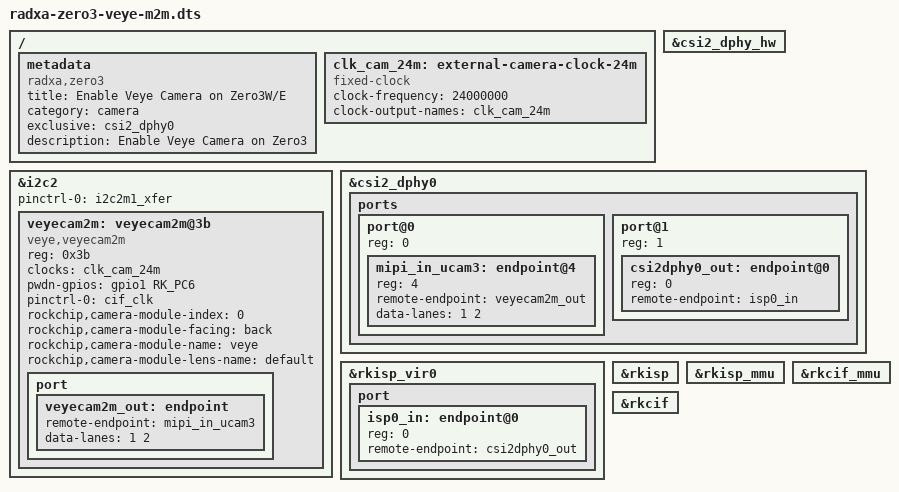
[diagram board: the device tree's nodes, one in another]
/*
 * Copyright (C) 2024 Raphael from OpenHD
 *
 * This is free software: you can redistribute it and/or modify
 * it under the terms of the GNU General Public License as published by
 * the Free Software Foundation, either version 3 of the License, or
 * (at your option) any later version.
 *
 * This is distributed in the hope that it will be useful,
 * but WITHOUT ANY WARRANTY; without even the implied warranty of
 * MERCHANTABILITY or FITNESS FOR A PARTICULAR PURPOSE. See the
 * GNU General Public License for more details.
 *
 */

/dts-v1/;
/plugin/;

#include <dt-bindings/gpio/gpio.h>
#include <dt-bindings/pinctrl/rockchip.h>

/ {
	metadata {
		title = "Enable Veye Camera on Zero3W/E";
		compatible = "radxa,zero3";
		category = "camera";
		exclusive = "csi2_dphy0";
		description = "Enable Veye Camera on Zero3";
	};

	fragment@0 {
		target-path = "/";

		__overlay__ {		
			clk_cam_24m: external-camera-clock-24m {
				status = "okay";
				compatible = "fixed-clock";
				clock-frequency = <24000000>;
				clock-output-names = "clk_cam_24m";
				#clock-cells = <0>;
			};
		};
	};

	fragment@1 {
		target = <&i2c2>;

		__overlay__ {
			status = "okay";
			pinctrl-names = "default";
			pinctrl-0 = <&i2c2m1_xfer>;
			#address-cells = <1>;
			#size-cells = <0>;

			veyecam2m: veyecam2m@3b {
				status = "okay";
				compatible = "veye,veyecam2m";
				reg = <0x3b>;
				clocks = <&clk_cam_24m>;
		 		clock-names = "xvclk";
				pwdn-gpios = <&gpio1 RK_PC6 GPIO_ACTIVE_HIGH>;
				pinctrl-names = "default";
				pinctrl-0 = <&cif_clk>;
				rockchip,camera-module-index = <0>;
				rockchip,camera-module-facing = "back";
				rockchip,camera-module-name = "veye";
				rockchip,camera-module-lens-name = "default";

				port {
					veyecam2m_out: endpoint {
						remote-endpoint = <&mipi_in_ucam3>;
						data-lanes = <1 2>;
					};
				};
			};
		};
	};

	fragment@2 {
		target = <&csi2_dphy_hw>;

		__overlay__ {
			status = "okay";
		};
	};

	fragment@3 {
		target = <&csi2_dphy0>;

		__overlay__ {
			status = "okay";

			ports {
				#address-cells = <1>;
				#size-cells = <0>;

				port@0 {
					reg = <0>;
					#address-cells = <1>;
					#size-cells = <0>;

					mipi_in_ucam3: endpoint@4 {
						reg = <4>;
						remote-endpoint = <&veyecam2m_out>;
						data-lanes = <1 2>;
					};
				};

				port@1 {
					reg = <1>;
					#address-cells = <1>;
					#size-cells = <0>;

					csi2dphy0_out: endpoint@0 {
						reg = <0>;
						remote-endpoint = <&isp0_in>;
					};
				};
			};
		};
	};

	fragment@4 {
		target = <&rkisp_vir0>;

		__overlay__ {
			status = "okay";

			port {
				#address-cells = <1>;
				#size-cells = <0>;

				isp0_in: endpoint@0 {
					reg = <0>;
					remote-endpoint = <&csi2dphy0_out>;
				};
			};
		};
	};

	fragment@5 {
		target = <&rkisp>;

		__overlay__ {
			status = "okay";
		};
	};

	fragment@6 {
		target = <&rkisp_mmu>;

		__overlay__ {
			status = "okay";
		};
	};

	fragment@7 {
		target = <&rkcif_mmu>;

		__overlay__ {
			status = "okay";
		};
	};

	fragment@8 {
		target = <&rkcif>;

		__overlay__ {
			status = "okay";
		};
	};

};
